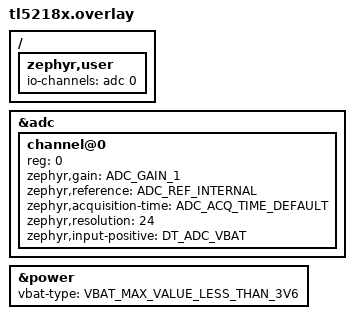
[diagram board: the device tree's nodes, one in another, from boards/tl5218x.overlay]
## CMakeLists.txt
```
#
#    Copyright (c) 2023-2026 Project CHIP Authors
#
#    Licensed under the Apache License, Version 2.0 (the "License");
#    you may not use this file except in compliance with the License.
#    You may obtain a copy of the License at
#
#        http://www.apache.org/licenses/LICENSE-2.0
#
#    Unless required by applicable law or agreed to in writing, software
#    distributed under the License is distributed on an "AS IS" BASIS,
#    WITHOUT WARRANTIES OR CONDITIONS OF ANY KIND, either express or implied.
#    See the License for the specific language governing permissions and
#    limitations under the License.
#

cmake_minimum_required(VERSION 3.20)

get_filename_component(CHIP_ROOT ${CMAKE_CURRENT_SOURCE_DIR}/third_party/connectedhomeip REALPATH)
get_filename_component(TELINK_COMMON ${CHIP_ROOT}/examples/platform/telink REALPATH)
get_filename_component(GEN_DIR ${CHIP_ROOT}/zzz_generated/ REALPATH)

include(${TELINK_COMMON}/common.cmake)
include(${CHIP_ROOT}/config/telink/app/enable-gnu-std.cmake)
include(${CHIP_ROOT}/src/app/chip_data_model.cmake)

project(chip-telink-lock-example)

target_include_directories(app PRIVATE
                           include
                           ${GEN_DIR}/app-common
                           ${GEN_DIR}/lock-app
                           ${TELINK_COMMON}/common/include
                           ${TELINK_COMMON}/util/include
                           ${TELINK_COMMON}/app/include
                           ${TELINK_COMMON}/zephyr_ext)

target_sources(app PRIVATE
               src/AppTask.cpp
               src/AliroDelegate.cpp
               src/ZclCallbacks.cpp
               src/LockManager.cpp
               src/LockSettingsStorage.cpp
               ${TELINK_COMMON}/common/src/mainCommon.cpp
               ${TELINK_COMMON}/common/src/AppTaskCommon.cpp
               ${TELINK_COMMON}/util/src/LEDManager.cpp
               ${TELINK_COMMON}/util/src/ButtonManager.cpp
               ${TELINK_COMMON}/util/src/ThreadUtil.cpp
               ${TELINK_COMMON}/util/src/PWMManager.cpp
               ${TELINK_COMMON}/zephyr_ext/zephyr_key_matrix.c
               ${TELINK_COMMON}/zephyr_ext/zephyr_key_pool.c
               ${TELINK_COMMON}/zephyr_ext/zephyr_led_pool.c
               ${TELINK_COMMON}/zephyr_ext/zephyr_pwm_pool.c
               ${TELINK_COMMON}/zephyr_ext/zephyr_ws2812.c
               ${TELINK_COMMON}/zephyr_ext/zephyr_pm_observer.c)

chip_configure_data_model(app
    ZAP_FILE ${CMAKE_CURRENT_SOURCE_DIR}/../lock-common/lock-app.zap
)

if(CONFIG_TELINK_BATTERY_MONITOR)
  target_sources(app PRIVATE
    src/BatteryReporter.cpp
    ${TELINK_COMMON}/common/src/BatteryMonitor.c
    ${TELINK_COMMON}/common/src/BatteryMonitorLogic.c
    ${TELINK_COMMON}/common/src/BatterySafeMode.cpp
  )
endif()

if(CONFIG_BOOTLOADER_MCUBOOT)
  target_sources(app PRIVATE ${TELINK_COMMON}/util/src/OTAUtil.cpp)
endif()
```

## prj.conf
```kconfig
#
#    Copyright (c) 2023-2026 Project CHIP Authors
#
#    Licensed under the Apache License, Version 2.0 (the "License");
#    you may not use this file except in compliance with the License.
#    You may obtain a copy of the License at
#
#        http://www.apache.org/licenses/LICENSE-2.0
#
#    Unless required by applicable law or agreed to in writing, software
#    distributed under the License is distributed on an "AS IS" BASIS,
#    WITHOUT WARRANTIES OR CONDITIONS OF ANY KIND, either express or implied.
#    See the License for the specific language governing permissions and
#    limitations under the License.
#

# This sample uses Kconfig.defaults to set options common for all
# samples. This file should contain only options specific for this sample
# or overrides of default values.

# Enable CHIP
CONFIG_CHIP=y
CONFIG_STD_CPP20=y

# 32774 == 0x8006 (example lock-app)
CONFIG_CHIP_DEVICE_PRODUCT_ID=32774

# Bluetooth Low Energy configuration
CONFIG_BT_DEVICE_NAME="TelinkLock"

# Disable Matter OTA DFU
CONFIG_CHIP_OTA_REQUESTOR=n
CONFIG_CHIP_DEVICE_SOFTWARE_VERSION=1

# Disable CHIP shell support
CONFIG_CHIP_LIB_SHELL=n

# Disable factory data support
CONFIG_CHIP_FACTORY_DATA=n
CONFIG_CHIP_FACTORY_DATA_BUILD=n
CONFIG_CHIP_FACTORY_DATA_MERGE_WITH_FIRMWARE=n

# Enable Power Management
CONFIG_PM=y

# VBAT monitoring (Power Source cluster)
CONFIG_ADC=y
CONFIG_REBOOT=y
CONFIG_TELINK_BATTERY_MONITOR=y

# compress ota
CONFIG_COMPRESS_LZMA=y
CONFIG_LZMA=y

# ICD SETTING INFO
CONFIG_CHIP_ICD_SLOW_POLL_INTERVAL=7500
CONFIG_CHIP_ICD_FAST_POLLING_INTERVAL=200
CONFIG_CHIP_ICD_ACTIVE_MODE_THRESHOLD=300
CONFIG_CHIP_ICD_IDLE_MODE_DURATION=900

# matter switch mode
# config NORMAL_MODE    0 independent matter mode
# ACTION_DUAL_MODE      1 matter action switch mode ,such as by button
# AUTO_SWITCH_DUAL_MODE 2 matter auto-switch mode ,such as by scan QR code.
CONFIG_DUAL_MODE=0

# Secure programming requires CONFIG_CHIP_FACTORY_DATA and
# CONFIG_CHIP_CERTIFICATION_DECLARATION_STORAGE to be enabled.
CONFIG_SECURE_PROGRAMMING=n

# Enable CHIP-ID via ble
CONFIG_EXPOSE_CHIP_ID_VIA_BLE=n

# Enable Deferred Store Attribute
CONFIG_DEFERRED_ATTR_STORAGE=n

# CONFIG_MCUBOOT_SIGNATURE_KEY_FILE="bootloader/mcuboot/ecdsa_private_key.pem"
```

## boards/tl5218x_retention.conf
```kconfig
#compress ota
CONFIG_LZMA=y
CONFIG_COMPRESS_LZMA=y

CONFIG_ADC_TL521X_ACQUISITION_THREAD_STACK_SIZE=1024

#matter switch mode
# config NORMAL_MODE    0 independent matter mode
# ACTION_DUAL_MODE      1 matter action switch mode ,such as by button
# AUTO_SWITCH_DUAL_MODE 2 matter auto-switch mode ,such as by scan QR code.
CONFIG_DUAL_MODE=1
```

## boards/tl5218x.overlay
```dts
/*
 * SPDX-License-Identifier: Apache-2.0
 *
 * Copyright (c) 2026 Telink Semiconductor (Shanghai) Co., Ltd.
 */

/ {
	zephyr,user {
		io-channels = <&adc 0>;
	};
};

&adc {
	#address-cells = <1>;
	#size-cells = <0>;

	channel@0 {
		reg = <0>;
		zephyr,gain = "ADC_GAIN_1";
		zephyr,reference = "ADC_REF_INTERNAL";
		zephyr,acquisition-time = <ADC_ACQ_TIME_DEFAULT>;
		zephyr,resolution = <24>;
		zephyr,input-positive = <DT_ADC_VBAT>;
	};
};

&power {
	vbat-type = "VBAT_MAX_VALUE_LESS_THAN_3V6";
};
```

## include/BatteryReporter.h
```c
/*
 *
 *    Copyright (c) 2026 Project CHIP Authors
 *
 *    Licensed under the Apache License, Version 2.0 (the "License");
 *    you may not use this file except in compliance with the License.
 *    You may obtain a copy of the License at
 *
 *        http://www.apache.org/licenses/LICENSE-2.0
 *
 *    Unless required by applicable law or agreed to in writing, software
 *    distributed under the License is distributed on an "AS IS" BASIS,
 *    WITHOUT WARRANTIES OR CONDITIONS OF ANY KIND, either express or implied.
 *    See the License for the specific language governing permissions and
 *    limitations under the License.
 */

#pragma once

#include <lib/core/CHIPError.h>

class BatteryReporter
{
public:
    /**
     * Find the battery Power Source endpoint and start the VBAT monitor.
     */
    static chip::ChipError Init();
};
```

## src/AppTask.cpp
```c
/*
 *
 *    Copyright (c) 2023-2024 Project CHIP Authors
 *    All rights reserved.
 *
 *    Licensed under the Apache License, Version 2.0 (the "License");
 *    you may not use this file except in compliance with the License.
 *    You may obtain a copy of the License at
 *
 *        http://www.apache.org/licenses/LICENSE-2.0
 *
 *    Unless required by applicable law or agreed to in writing, software
 *    distributed under the License is distributed on an "AS IS" BASIS,
 *    WITHOUT WARRANTIES OR CONDITIONS OF ANY KIND, either express or implied.
 *    See the License for the specific language governing permissions and
 *    limitations under the License.
 */

#include "AppTask.h"
#include "AliroDelegate.h"
#include "BatteryReporter.h"
#include "ButtonManager.h"
#include "LEDManager.h"
#include <LockManager.h>
#include <app-common/zap-generated/attributes/Accessors.h>
#include <app/data-model/Nullable.h>
#include <app/server/Server.h>
#include <credentials/FabricTable.h>

LOG_MODULE_DECLARE(app, CONFIG_CHIP_APP_LOG_LEVEL);

using namespace ::chip::app::Clusters::DoorLock;
using namespace chip;
using namespace chip::app;
using namespace ::chip::DeviceLayer;
using namespace ::chip::DeviceLayer::Internal;
using namespace TelinkDoorLock::LockInitParams;

AppTask AppTask::sAppTask;

CHIP_ERROR AppTask::Init(void)
{
    SetExampleButtonCallbacks(LockActionEventHandler);
    ReturnErrorOnFailure(InitCommonParts());
    ReturnErrorOnFailure(BatteryReporter::Init());

    LedManager::getInstance().setLed(LedManager::EAppLed_App0, LockMgr().IsLocked());

    chip::app::DataModel::Nullable<chip::app::Clusters::DoorLock::DlLockState> state;
    chip::EndpointId endpointId{ kExampleEndpointId };
    chip::DeviceLayer::PlatformMgr().LockChipStack();
    chip::app::Clusters::DoorLock::Attributes::LockState::Get(endpointId, state);

    uint8_t numberOfCredentialsPerUser = 0;
    if (!DoorLockServer::Instance().GetNumberOfCredentialsSupportedPerUser(endpointId, numberOfCredentialsPerUser))
    {
        ChipLogError(Zcl,
                     "Unable to get number of credentials supported per user when initializing lock endpoint, defaulting to %d "
                     "[endpointId=%d]",
                     APP_DEFAULT_CREDENTIAL_COUNT, endpointId);
        numberOfCredentialsPerUser = APP_DEFAULT_CREDENTIAL_COUNT;
    }

    uint16_t numberOfUsers = 0;
    if (!DoorLockServer::Instance().GetNumberOfUserSupported(endpointId, numberOfUsers))
    {
        ChipLogError(Zcl,
                     "Unable to get number of supported users when initializing lock endpoint, defaulting to %d [endpointId=%d]",
                     APP_DEFAULT_USERS_COUNT, endpointId);
        numberOfUsers = APP_DEFAULT_USERS_COUNT;
    }

    uint8_t numberOfWeekdaySchedulesPerUser = 0;
    if (!DoorLockServer::Instance().GetNumberOfWeekDaySchedulesPerUserSupported(endpointId, numberOfWeekdaySchedulesPerUser))
    {
        ChipLogError(
            Zcl,
            "Unable to get number of supported weekday schedules when initializing lock endpoint, defaulting to %d [endpointId=%d]",
            APP_DEFAULT_WEEKDAY_SCHEDULE_PER_USER_COUNT, endpointId);
        numberOfWeekdaySchedulesPerUser = APP_DEFAULT_WEEKDAY_SCHEDULE_PER_USER_COUNT;
    }

    uint8_t numberOfYeardaySchedulesPerUser = 0;
    if (!DoorLockServer::Instance().GetNumberOfYearDaySchedulesPerUserSupported(endpointId, numberOfYeardaySchedulesPerUser))
    {
        ChipLogError(
            Zcl,
            "Unable to get number of supported yearday schedules when initializing lock endpoint, defaulting to %d [endpointId=%d]",
            APP_DEFAULT_YEARDAY_SCHEDULE_PER_USER_COUNT, endpointId);
        numberOfYeardaySchedulesPerUser = APP_DEFAULT_YEARDAY_SCHEDULE_PER_USER_COUNT;
    }

    uint8_t numberOfHolidaySchedules = 0;
    if (!DoorLockServer::Instance().GetNumberOfHolidaySchedulesSupported(endpointId, numberOfHolidaySchedules))
    {
        ChipLogError(
            Zcl,
            "Unable to get number of supported holiday schedules when initializing lock endpoint, defaulting to %d [endpointId=%d]",
            APP_DEFAULT_HOLYDAY_SCHEDULE_PER_USER_COUNT, endpointId);
        numberOfHolidaySchedules = APP_DEFAULT_HOLYDAY_SCHEDULE_PER_USER_COUNT;
    }

    chip::DeviceLayer::PlatformMgr().UnlockChipStack();

    CHIP_ERROR err = CHIP_NO_ERROR;

    err = LockMgr().Init(state,
                         ParamBuilder()
                             .SetNumberOfUsers(numberOfUsers)
                             .SetNumberOfCredentialsPerUser(numberOfCredentialsPerUser)
                             .SetNumberOfWeekdaySchedulesPerUser(numberOfWeekdaySchedulesPerUser)
                             .SetNumberOfYeardaySchedulesPerUser(numberOfYeardaySchedulesPerUser)
                             .SetNumberOfHolidaySchedules(numberOfHolidaySchedules)
                             .GetLockParam(),
                         LockStateChanged);

    if (err != CHIP_NO_ERROR)
    {
        LOG_ERR("LockMgr().Init() failed");
        return err;
    }

    // Disable auto-relock time feature.
    DoorLockServer::Instance().SetAutoRelockTime(kExampleEndpointId, 0);

    // Register a Door Lock delegate to handle Aliro provisioning attributes/commands.
    DoorLockServer::Instance().SetDelegate(kExampleEndpointId, &AliroDelegate::GetInstance());

    return CHIP_NO_ERROR;
}

/* This is a button handler only */
void AppTask::LockActionEventHandler(AppEvent * aEvent)
{
    switch (LockMgr().getLockState())
    {
    case LockManager::kState_NotFulyLocked:
    case LockManager::kState_LockCompleted:
        LockMgr().LockAction(AppEvent::kEventType_DeviceAction, LockManager::UNLOCK_ACTION, LockManager::OperationSource::kButton,
                             kExampleEndpointId);
        break;
    case LockManager::kState_UnlockCompleted:
        LockMgr().LockAction(AppEvent::kEventType_DeviceAction, LockManager::LOCK_ACTION, LockManager::OperationSource::kButton,
                             kExampleEndpointId);
        break;
    default:
        LOG_INF("Lock is in intermediate state, ignoring button");
        break;
    }
}

void AppTask::LockStateChanged(LockManager::State_t state)
{
    switch (state)
    {
    case LockManager::State_t::kState_LockInitiated:
        LOG_INF("Callback: Lock action initiated");
        LedManager::getInstance().setLed(LedManager::EAppLed_App0, 50, 50);
        break;
    case LockManager::State_t::kState_LockCompleted:
        LOG_INF("Callback: Lock action completed");
        LedManager::getInstance().setLed(LedManager::EAppLed_App0, true);
        break;
    case LockManager::State_t::kState_UnlockInitiated:
        LOG_INF("Callback: Unlock action initiated");
        LedManager::getInstance().setLed(LedManager::EAppLed_App0, 50, 50);
        break;
    case LockManager::State_t::kState_UnlockCompleted:
        LOG_INF("Callback: Unlock action completed");
        LedManager::getInstance().setLed(LedManager::EAppLed_App0, false);
        break;
    case LockManager::State_t::kState_UnlatchInitiated:
        LOG_INF("Callback: Unbolt action initiated");
        LedManager::getInstance().setLed(LedManager::EAppLed_App0, 75, 25);
        break;
    case LockManager::State_t::kState_UnlatchCompleted:
        LOG_INF("Callback: Unbolt action completed");
        LedManager::getInstance().setLed(LedManager::EAppLed_App0, 25, 75);
        break;
    case LockManager::State_t::kState_NotFulyLocked:
        LOG_INF("Callback: Lock not fully locked. Unexpected state");
        LedManager::getInstance().setLed(LedManager::EAppLed_App0, 10, 90);
        break;
    }
}

void AppTask::LockJammedEventHandler(void)
{
    AppEvent event;

    event.Type               = AppEvent::kEventType_Button;
    event.ButtonEvent.Action = kButtonPushEvent;
    event.Handler            = LockJammedActionHandler;
    GetAppTask().PostEvent(&event);
}

void AppTask::LockJammedActionHandler(AppEvent * aEvent)
{
    LOG_INF("Sending a lock jammed event");

    /* Generating Door Lock Jammed event */
    DoorLockServer::Instance().SendLockAlarmEvent(kExampleEndpointId, AlarmCodeEnum::kLockJammed);
}

void AppTask::LockStateEventHandler(void)
{
    AppEvent event;

    event.Type               = AppEvent::kEventType_Button;
    event.ButtonEvent.Action = kButtonPushEvent;
    event.Handler            = LockStateActionHandler;
    GetAppTask().PostEvent(&event);
}

void AppTask::LockStateActionHandler(AppEvent * aEvent)
{
    LOG_INF("Sending a lock state event");

    // This code was written for testing purpose only
    // For real door status the level detection may be used instead of pulse
    static DoorStateEnum mDoorState = DoorStateEnum::kDoorOpen;
    if (mDoorState == DoorStateEnum::kDoorOpen)
    {
        mDoorState = DoorStateEnum::kDoorClosed;
    }
    else
    {
        mDoorState = DoorStateEnum::kDoorOpen;
    }

    /* Generating Door Lock Status event */
    DoorLockServer::Instance().SetDoorState(kExampleEndpointId, mDoorState);
}

void AppTask::LinkButtons(ButtonManager & buttonManager)
{
    buttonManager.addCallback(FactoryResetButtonEventHandler, 0, true);
    buttonManager.addCallback(ExampleActionButtonEventHandler, 1, true);
    buttonManager.addCallback(LockJammedEventHandler, 2, true);
    buttonManager.addCallback(LockStateEventHandler, 3, true);
}

void AppTask::LinkLeds(LedManager & ledManager)
{
#if CONFIG_CHIP_ENABLE_APPLICATION_STATUS_LED
    ledManager.linkLed(LedManager::EAppLed_Status, 0);
    ledManager.linkLed(LedManager::EAppLed_App0, 1);
#else
    ledManager.linkLed(LedManager::EAppLed_App0, 0);
#endif // CONFIG_CHIP_ENABLE_APPLICATION_STATUS_LED
}
```

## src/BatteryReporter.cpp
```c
/*
 *
 *    Copyright (c) 2026 Project CHIP Authors
 *
 *    Licensed under the Apache License, Version 2.0 (the "License");
 *    you may not use this file except in compliance with the License.
 *    You may obtain a copy of the License at
 *
 *        http://www.apache.org/licenses/LICENSE-2.0
 *
 *    Unless required by applicable law or agreed to in writing, software
 *    distributed under the License is distributed on an "AS IS" BASIS,
 *    WITHOUT WARRANTIES OR CONDITIONS OF ANY KIND, either express or implied.
 *    See the License for the specific language governing permissions and
 *    limitations under the License.
 */

#include "BatteryReporter.h"

#include <errno.h>

#include <app-common/zap-generated/attributes/Accessors.h>
#include <app-common/zap-generated/ids/Clusters.h>
#include <app/clusters/power-source-server/power-source-server.h>
#include <app/util/MarkAttributeDirty.h>
#include <app/util/attribute-storage.h>
#include <lib/support/CodeUtils.h>
#include <lib/support/logging/CHIPLogging.h>
#include <platform/CHIPDeviceLayer.h>

#include "BatteryMonitor.h"

using namespace chip;
using namespace chip::app;

namespace {

using namespace chip::app::Clusters;

EndpointId sEndpoint = kInvalidEndpointId;

EndpointId FindBatteryEndpoint()
{
    for (EndpointId endpoint : EnabledEndpointsWithServerCluster(PowerSource::Id))
    {
        uint32_t featureMap = 0;

        if (PowerSource::Attributes::FeatureMap::Get(endpoint, &featureMap) ==
                Protocols::InteractionModel::Status::Success &&
            (featureMap & static_cast<uint32_t>(PowerSource::Feature::kBattery)) != 0)
        {
            return endpoint;
        }
    }

    return kInvalidEndpointId;
}

void OnBatteryStatus(const battery_status_t * status, void * userData)
{
    (void) userData;

    if (status == nullptr || !status->valid || sEndpoint == kInvalidEndpointId)
    {
        return;
    }

    const uint32_t voltage_mv = status->voltage_mv;
    const uint8_t percent_x2  = status->percent_x2;
    const uint8_t level       = static_cast<uint8_t>(status->level);

    /* The monitor runs in the Zephyr work queue; touch the data model from the CHIP task. */
    TEMPORARY_RETURN_IGNORED DeviceLayer::SystemLayer().ScheduleLambda([voltage_mv, percent_x2, level] {
        (void) PowerSource::Attributes::BatVoltage::Set(sEndpoint, voltage_mv, MarkAttributeDirty::kNo);
        (void) PowerSource::Attributes::BatPercentRemaining::Set(sEndpoint, percent_x2, MarkAttributeDirty::kIfChanged);
        (void) PowerSource::Attributes::BatChargeLevel::Set(
            sEndpoint, static_cast<PowerSource::BatChargeLevelEnum>(level), MarkAttributeDirty::kIfChanged);
    });
}

} // namespace

CHIP_ERROR BatteryReporter::Init()
{
    sEndpoint = FindBatteryEndpoint();
    if (sEndpoint == kInvalidEndpointId)
    {
        ChipLogError(NotSpecified, "BatteryReporter: no battery PowerSource endpoint");
        return CHIP_ERROR_NOT_FOUND;
    }

    EndpointId endpointList[] = { sEndpoint };
    CHIP_ERROR err = Clusters::PowerSourceServer::Instance().SetEndpointList(sEndpoint, Span<EndpointId>(endpointList, 1));
    if (err != CHIP_NO_ERROR)
    {
        ChipLogError(NotSpecified, "BatteryReporter: SetEndpointList failed: %" CHIP_ERROR_FORMAT, err.Format());
    }

    battery_monitor_config_t config;

    battery_monitor_config_defaults(&config);
    config.action = BATTERY_ACTION_SAFE_MODE;

    int rc = battery_monitor_init(&config);
    if (rc != 0 && rc != -EALREADY)
    {
        ChipLogError(NotSpecified, "BatteryReporter: battery_monitor_init failed: %d", rc);
        return CHIP_ERROR_INTERNAL;
    }

    if (battery_monitor_is_latched())
    {
        battery_monitor_action_hook(BATTERY_ACTION_SAFE_MODE);
    }

    rc = battery_monitor_start(OnBatteryStatus, nullptr);
    if (rc != 0)
    {
        ChipLogError(NotSpecified, "BatteryReporter: battery_monitor_start failed: %d", rc);
        return CHIP_ERROR_INTERNAL;
    }

    ChipLogProgress(NotSpecified, "BatteryReporter: reporting on endpoint %u", sEndpoint);
    return CHIP_NO_ERROR;
}
```
